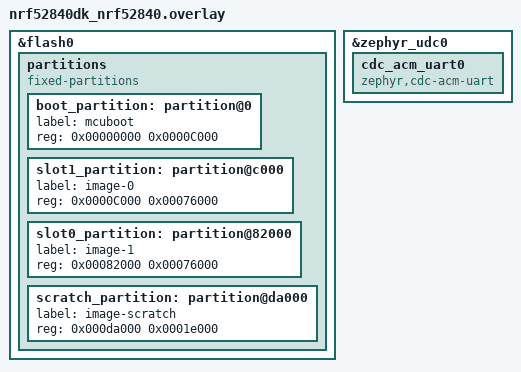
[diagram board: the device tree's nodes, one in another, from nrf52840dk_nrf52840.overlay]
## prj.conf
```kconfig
CONFIG_STDOUT_CONSOLE=y
CONFIG_USB_DEVICE_STACK=y
CONFIG_USB_DEVICE_BOS=y
CONFIG_SERIAL=y
CONFIG_USB_DEVICE_PRODUCT="Zephyr WebUSB sample"
CONFIG_USB_DEVICE_PID=0x000A
CONFIG_UART_INTERRUPT_DRIVEN=y
CONFIG_UART_LINE_CTRL=y
CONFIG_USB_DEVICE_INITIALIZE_AT_BOOT=n

CONFIG_LOG=y
CONFIG_USB_DRIVER_LOG_LEVEL_ERR=y
CONFIG_USB_DEVICE_LOG_LEVEL_ERR=y

CONFIG_FLASH=y
CONFIG_FLASH_MAP=y
CONFIG_STREAM_FLASH=y
CONFIG_IMG_MANAGER=y
CONFIG_FLASH_PAGE_LAYOUT=y

CONFIG_BOOTLOADER_MCUBOOT=y
CONFIG_MCUBOOT_EXTRA_IMGTOOL_ARGS="--version 1.2"
CONFIG_MCUBOOT_SIGNATURE_KEY_FILE="bootloader/mcuboot/root-rsa-2048.pem"
```

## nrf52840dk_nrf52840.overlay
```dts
/delete-node/ &boot_partition;
/delete-node/ &slot0_partition;
/delete-node/ &slot1_partition;
&flash0 {
    partitions {
            compatible = "fixed-partitions";
            #address-cells = <1>;
            #size-cells = <1>;
            boot_partition: partition@0 {
                label = "mcuboot";
                reg = <0x00000000 0x0000C000>;
            };
            slot1_partition: partition@c000 {
                label = "image-0";
                reg = <0x0000C000 0x00076000>;
            };
            slot0_partition: partition@82000 {
                label = "image-1";
                reg = <0x00082000 0x00076000>;
            };
            scratch_partition: partition@da000 {
                label = "image-scratch";
                reg = <0x000da000 0x0001e000>;
            };
    };
};
&zephyr_udc0 {
    cdc_acm_uart0 {
        compatible = "zephyr,cdc-acm-uart";
    };
};
```

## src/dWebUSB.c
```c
#define LOG_LEVEL CONFIG_USB_DEVICE_LOG_LEVEL
#include <zephyr/logging/log.h>
LOG_MODULE_REGISTER(webusb);

#include <zephyr/sys/byteorder.h>
#include <zephyr/usb/usb_device.h>
#include <usb_descriptor.h>

#include "dWebUSB.h"

#include <stdio.h>
#include <stdlib.h>
#include </home/peter/dfwebusb/zephyr/include/zephyr/dfu/mcuboot.h>

/* Max packet size for Bulk endpoints */
#if IS_ENABLED(CONFIG_USB_DC_HAS_HS_SUPPORT)
#define WEBUSB_BULK_EP_MPS		512
#else
#define WEBUSB_BULK_EP_MPS		64
#endif

/* Number of interfaces */
#define WEBUSB_NUM_ITF			0x01
/* Number of Endpoints in the custom interface */
#define WEBUSB_NUM_EP			0x02

#define WEBUSB_IN_EP_IDX		0
#define WEBUSB_OUT_EP_IDX		1

static struct webusb_req_handlers *req_handlers;

#define TX_MEM_ERROR 	0x05
#define TX_SIZE			20000
//setting up a buffers for echoing received data
uint8_t rx_buf[WEBUSB_BULK_EP_MPS];
static uint8_t tx_buf[TX_SIZE];
static size_t bytes_count = 0;

//template for interface descriptors
#define INITIALIZER_IF(num_ep, iface_class)				\
	{								\
		.bLength = sizeof(struct usb_if_descriptor),		\
		.bDescriptorType = USB_DESC_INTERFACE,			\
		.bInterfaceNumber = 0,					\
		.bAlternateSetting = 0,					\
		.bNumEndpoints = num_ep,				\
		.bInterfaceClass = iface_class,				\
		.bInterfaceSubClass = 0,				\
		.bInterfaceProtocol = 0,				\
		.iInterface = 0,					\
	}
//template for endpoint descriptors
#define INITIALIZER_IF_EP(addr, attr, mps, interval)			\
	{								\
		.bLength = sizeof(struct usb_ep_descriptor),		\
		.bDescriptorType = USB_DESC_ENDPOINT,			\
		.bEndpointAddress = addr,				\
		.bmAttributes = attr,					\
		.wMaxPacketSize = sys_cpu_to_le16(mps),			\
		.bInterval = interval,					\
	}
//initialise interface and endpoints descriptors
USBD_CLASS_DESCR_DEFINE(primary, 0) struct {
	struct usb_if_descriptor if0;
	struct usb_ep_descriptor if0_in_ep;
	struct usb_ep_descriptor if0_out_ep;
} __packed webusb_desc = {
	.if0 = INITIALIZER_IF(WEBUSB_NUM_EP, USB_BCC_VENDOR),
	.if0_in_ep = INITIALIZER_IF_EP(AUTO_EP_IN, USB_DC_EP_BULK,
				       WEBUSB_BULK_EP_MPS, 0),
	.if0_out_ep = INITIALIZER_IF_EP(AUTO_EP_OUT, USB_DC_EP_BULK,
					WEBUSB_BULK_EP_MPS, 0),
};

/**
 * @brief Custom handler for standard requests in order to
 *        catch the request and return the WebUSB Platform
 *        Capability Descriptor.
 *
 * @param pSetup    Information about the request to execute.
 * @param len       Size of the buffer.
 * @param data      Buffer containing the request result.
 *
 * @return  0 on success, negative errno code on fail.
 */
int webusb_custom_handle_req(struct usb_setup_packet *pSetup,
			     int32_t *len, uint8_t **data){
	LOG_DBG("");

	/* Call the callback */
	if (req_handlers && req_handlers->custom_handler) {
		return req_handlers->custom_handler(pSetup, len, data);
	}

	return -EINVAL;
}

/**
 * @brief Handler called for WebUSB vendor specific commands.
 *
 * @param pSetup    Information about the request to execute.
 * @param len       Size of the buffer.
 * @param data      Buffer containing the request result.
 *
 * @return  0 on success, negative errno code on fail.
 */
int webusb_vendor_handle_req(struct usb_setup_packet *pSetup,
			     int32_t *len, uint8_t **data){
	/* Call the callback */
	if (req_handlers && req_handlers->vendor_handler) {
		return req_handlers->vendor_handler(pSetup, len, data);
	}

	return -EINVAL;
}

/**
 * @brief Register Custom and Vendor request callbacks
 *
 * This function registers Custom and Vendor request callbacks
 * for handling the device requests.
 *
 * @param [in] handlers Pointer to WebUSB request handlers structure
 */
void webusb_register_request_handlers(struct webusb_req_handlers *handlers){
	req_handlers = handlers;
}

static void webusb_write_cb(uint8_t ep, int size, void *priv){
	//printf("\n This is write callback, ep %x size %u", ep, size);
	bytes_count = 0;
	memset(tx_buf, 0, sizeof(tx_buf)); //zeroing the receiving array
}

static void webusb_read_cb(uint8_t ep, int size, void *priv){
	struct usb_cfg_data *cfg = priv;
	//printf("\nSize count: %d", size);
	
	if(size <= 0) goto done;
	else {
		//printf("\ntransfer still active");
		memcpy(tx_buf + bytes_count, rx_buf, size);
		bytes_count += size;
		//printf("\nBytes count: %zu", bytes_count);
		if(size < WEBUSB_BULK_EP_MPS && size > 0){
		//	printf("\ntransfer finished, ready to echo");
			usb_transfer(cfg->endpoint[WEBUSB_IN_EP_IDX].ep_addr, tx_buf, bytes_count,
				USB_TRANS_WRITE, webusb_write_cb, cfg);
		}
	}
done:
	usb_transfer(ep, rx_buf, sizeof(rx_buf), USB_TRANS_READ, webusb_read_cb, cfg);
	//printf("\nReading");
}

/**
 * @brief Callback used to know the USB connection status
 *
 * @param status USB device status code.
 */
static void webusb_dev_status_cb(struct usb_cfg_data *cfg,
				 enum usb_dc_status_code status,
				 const uint8_t *param){
	ARG_UNUSED(param);
	ARG_UNUSED(cfg);

	/* Check the USB status and do needed action if required */
	switch (status) {
	case USB_DC_ERROR:
		LOG_DBG("USB device error");
		break;
	case USB_DC_RESET:
		LOG_DBG("USB device reset detected");
		break;
	case USB_DC_CONNECTED:
		LOG_DBG("USB device connected");
		break;
	case USB_DC_CONFIGURED:
		LOG_DBG("USB device configured");
		webusb_read_cb(cfg->endpoint[WEBUSB_OUT_EP_IDX].ep_addr,
			       0, cfg);
		break;
	case USB_DC_DISCONNECTED:
		LOG_DBG("USB device disconnected");
		break;
	case USB_DC_SUSPEND:
		LOG_DBG("USB device suspended");
		break;
	case USB_DC_RESUME:
		LOG_DBG("USB device resumed");
		break;
	case USB_DC_UNKNOWN:
	default:
		LOG_DBG("USB unknown state");
		break;
	}
}

/* Describe EndPoints configuration */
static struct usb_ep_cfg_data webusb_ep_data[] = {
	{
		.ep_cb = usb_transfer_ep_callback,
		.ep_addr = AUTO_EP_IN
	},
	{
		.ep_cb	= usb_transfer_ep_callback,
		.ep_addr = AUTO_EP_OUT
	}
};

//USB Device configuration structure
USBD_DEFINE_CFG_DATA(webusb_config) = {
	.usb_device_description = NULL,
	.interface_descriptor = &webusb_desc.if0,
	.cb_usb_status = webusb_dev_status_cb,
	.interface = {
		.class_handler = NULL,
		.custom_handler = webusb_custom_handle_req,
		.vendor_handler = webusb_vendor_handle_req,
	},
	.num_endpoints = ARRAY_SIZE(webusb_ep_data),
	.endpoint = webusb_ep_data
};
```

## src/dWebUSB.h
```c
#ifndef __WEBUSB_SERIAL_H__
#define __WEBUSB_SERIAL_H__

/**
 * WebUSB request handlers
 */
struct webusb_req_handlers {
	/* Handler for WebUSB Vendor specific commands */
	usb_request_handler vendor_handler;
	/**
	 * The custom request handler gets a first chance at handling
	 * the request before it is handed over to the 'chapter 9' request
	 * handler
	 */
	usb_request_handler custom_handler;
};

/**
 * @brief Register Custom and Vendor request callbacks
 *
 * Function to register Custom and Vendor request callbacks
 * for handling requests.
 *
 * @param [in] handlers Pointer to WebUSB request handlers structure
 */
void webusb_register_request_handlers(struct webusb_req_handlers *handlers);

#endif /* __WEBUSB_SERIAL_H__ */
```

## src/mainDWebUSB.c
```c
#define LOG_LEVEL CONFIG_USB_DEVICE_LOG_LEVEL
#include <zephyr/logging/log.h>
LOG_MODULE_REGISTER(main);

#include <zephyr/sys/byteorder.h>
#include <zephyr/usb/usb_device.h>
#include <zephyr/usb/bos.h>

#include <zephyr/dfu/mcuboot.h>
#include "dWebUSB.h"
#include <stdio.h>

/* Number of allowed origins */
#define NUMBER_OF_ALLOWED_ORIGINS   1

//Error for unsuccesful image header read
#define READFW_ERROR -7
//structure for storing version data from an image read
static struct versionSend {
	uint8_t maj;
	uint8_t min;
	uint16_t rev;
} v;

/* Predefined response to control commands related to MS OS 2.0 descriptors */
static const uint8_t msos2_descriptor[] = {
	/* MS OS 2.0 set header descriptor   */
	0x0A, 0x00,             /* Descriptor size (10 bytes)                 */
	0x00, 0x00,             /* MS_OS_20_SET_HEADER_DESCRIPTOR             */
	0x00, 0x00, 0x03, 0x06, /* Windows version (8.1) (0x06030000)         */
	(0x0A + 0x14 + 0x08), 0x00, /* Length of the MS OS 2.0 descriptor set */

	/* MS OS 2.0 function subset ID descriptor
	 * This means that the descriptors below will only apply to one
	 * set of interfaces
	 */
	0x08, 0x00, /* Descriptor size (8 bytes) */
	0x02, 0x00, /* MS_OS_20_SUBSET_HEADER_FUNCTION */
	0x02,       /* Index of first interface this subset applies to. */
	0x00,       /* reserved */
	(0x08 + 0x14), 0x00, /* Length of the MS OS 2.0 descriptor subset */

	/* MS OS 2.0 compatible ID descriptor */
	0x14, 0x00, /* Descriptor size                */
	0x03, 0x00, /* MS_OS_20_FEATURE_COMPATIBLE_ID */
	/* 8-byte compatible ID string, then 8-byte sub-compatible ID string */
	'W',  'I',  'N',  'U',  'S',  'B',  0x00, 0x00,
	0x00, 0x00, 0x00, 0x00, 0x00, 0x00, 0x00, 0x00
};

/* WebUSB Platform Capability Descriptor:*/
USB_DEVICE_BOS_DESC_DEFINE_CAP struct usb_bos_webusb_desc {
	struct usb_bos_platform_descriptor platform;
	struct usb_bos_capability_webusb cap;
} __packed bos_cap_webusb = {
	/* https://wicg.github.io/webusb/#webusb-platform-capability-descriptor
	 *
	 * Size of the descriptor (must equal 24),
	 * Device capability descriptor type,
	 * Platform capability type ,
	 * Set to 0 for format purposes,
	 * Platform capability UUID
	 */
	.platform = {
		.bLength = sizeof(struct usb_bos_platform_descriptor)
			+ sizeof(struct usb_bos_capability_webusb),
		.bDescriptorType = USB_DESC_DEVICE_CAPABILITY,
		.bDevCapabilityType = USB_BOS_CAPABILITY_PLATFORM,
		.bReserved = 0,
		.PlatformCapabilityUUID = {
			0x38, 0xB6, 0x08, 0x34,
			0xA9, 0x09,
			0xA0, 0x47,
			0x8B, 0xFD,
			0xA0, 0x76, 0x88, 0x15, 0xB6, 0x65,
		},
	},

	/* Protocol version supported,
	 * bRequest value for webusb requests,
	 * URL desc index for landing page 
	 */
	.cap = {
		.bcdVersion = sys_cpu_to_le16(0x0100),
		.bVendorCode = 0x01,
		.iLandingPage = 0x01
	}
};

USB_DEVICE_BOS_DESC_DEFINE_CAP struct usb_bos_msosv2_desc {
	struct usb_bos_platform_descriptor platform;
	struct usb_bos_capability_msos cap;
} __packed bos_cap_msosv2 = {
	/* Microsoft OS 2.0 Platform Capability Descriptor
	 * See https://docs.microsoft.com/en-us/windows-hardware/drivers/usbcon/
	 * microsoft-defined-usb-descriptors
	 * Adapted from the source:
	 * https://github.com/sowbug/weblight/blob/master/firmware/webusb.c
	 * (BSD-2) Thanks http://janaxelson.com/files/ms_os_20_descriptors.c
	 */
	.platform = {
		.bLength = sizeof(struct usb_bos_platform_descriptor)
			+ sizeof(struct usb_bos_capability_msos),
		.bDescriptorType = USB_DESC_DEVICE_CAPABILITY,
		.bDevCapabilityType = USB_BOS_CAPABILITY_PLATFORM,
		.bReserved = 0,
		.PlatformCapabilityUUID = {
			/**
			 * MS OS 2.0 Platform Capability ID
			 * D8DD60DF-4589-4CC7-9CD2-659D9E648A9F
			 */
			0xDF, 0x60, 0xDD, 0xD8,
			0x89, 0x45,
			0xC7, 0x4C,
			0x9C, 0xD2,
			0x65, 0x9D, 0x9E, 0x64, 0x8A, 0x9F,
		},
	},
	.cap = {
		/* Windows version (8.1) (0x06030000) */
		.dwWindowsVersion = sys_cpu_to_le32(0x06030000),
		.wMSOSDescriptorSetTotalLength =
			sys_cpu_to_le16(sizeof(msos2_descriptor)),
		.bMS_VendorCode = 0x02,
		.bAltEnumCode = 0x00
	},
};

USB_DEVICE_BOS_DESC_DEFINE_CAP struct usb_bos_capability_lpm bos_cap_lpm = {
	.bLength = sizeof(struct usb_bos_capability_lpm),
	.bDescriptorType = USB_DESC_DEVICE_CAPABILITY,
	.bDevCapabilityType = USB_BOS_CAPABILITY_EXTENSION,
	/**
	 * BIT(1) - LPM support
	 * BIT(2) - BESL support
	 */
	.bmAttributes = BIT(1) | BIT(2),
};

/* WebUSB Device Requests */
static const uint8_t webusb_allowed_origins[] = {
	/* Allowed Origins Header:
	 * https://wicg.github.io/webusb/#get-allowed-origins
	 */
	0x05, 0x00, 0x0D, 0x00, 0x01,

	/* Configuration Subset Header:
	 * https://wicg.github.io/webusb/#configuration-subset-header
	 */
	0x04, 0x01, 0x01, 0x01,

	/* Function Subset Header:
	 * https://wicg.github.io/webusb/#function-subset-header
	 */
	0x04, 0x02, 0x02, 0x01
};

/* (Landing page) URL Descriptor: https://wicg.github.io/webusb/#url-descriptor */
static const uint8_t webusb_origin_url[] = {
	/* Length, DescriptorType, Scheme */
	0x1A, 0x03, 0x01,
    'd','e','l','t','a','-','w','e','b','u','s','b','.','v','e','r','c','e','l','.','a','p','p','/'
};

/* Predefined response to control commands related to MS OS 1.0 descriptors
 * Please note that this code only defines "extended compat ID OS feature
 * descriptors" and not "extended properties OS features descriptors"
 */
#define MSOS_STRING_LENGTH	18
static struct string_desc {
	uint8_t bLength;
	uint8_t bDescriptorType;
	uint8_t bString[MSOS_STRING_LENGTH];

} __packed msos1_string_descriptor = {
	.bLength = MSOS_STRING_LENGTH,
	.bDescriptorType = USB_DESC_STRING,
	/* Signature MSFT100 */
	.bString = {
		'M', 0x00, 'S', 0x00, 'F', 0x00, 'T', 0x00,
		'1', 0x00, '0', 0x00, '0', 0x00,
		0x03, /* Vendor Code, used for a control request */
		0x00, /* Padding byte for VendorCode looks like UTF16 */
	},
};

static const uint8_t msos1_compatid_descriptor[] = {
	/* See https://github.com/pbatard/libwdi/wiki/WCID-Devices */
	/* MS OS 1.0 header section */
	0x28, 0x00, 0x00, 0x00, /* Descriptor size (40 bytes)          */
	0x00, 0x01,             /* Version 1.00                        */
	0x04, 0x00,             /* Type: Extended compat ID descriptor */
	0x01,                   /* Number of function sections         */
	0x00, 0x00, 0x00, 0x00, 0x00, 0x00, 0x00,       /* reserved    */

	/* MS OS 1.0 function section */
	0x02,     /* Index of interface this section applies to. */
	0x01,     /* reserved */
	/* 8-byte compatible ID string, then 8-byte sub-compatible ID string */
	'W',  'I',  'N',  'U',  'S',  'B',  0x00, 0x00,
	0x00, 0x00, 0x00, 0x00, 0x00, 0x00, 0x00, 0x00,
	0x00, 0x00, 0x00, 0x00, 0x00, 0x00 /* reserved */
};

/**
 * @brief Custom handler for standard requests in
 *        order to catch the request and return the
 *        WebUSB Platform Capability Descriptor.
 *
 * @param pSetup    Information about the request to execute.
 * @param len       Size of the buffer.
 * @param data      Buffer containing the request result.
 *
 * @return  0 on success, negative errno code on fail
 */
int custom_handle_req(struct usb_setup_packet *pSetup,
		      int32_t *len, uint8_t **data){
	if (usb_reqtype_is_to_device(pSetup)) {
		return -ENOTSUP;
	}

	if (USB_GET_DESCRIPTOR_TYPE(pSetup->wValue) == USB_DESC_STRING &&
	    USB_GET_DESCRIPTOR_INDEX(pSetup->wValue) == 0xEE) {
		*data = (uint8_t *)(&msos1_string_descriptor);
		*len = sizeof(msos1_string_descriptor);

		LOG_DBG("Get MS OS Descriptor v1 string");

		return 0;
	}

	return -EINVAL;
}

/**
 * @brief Handler called for vendor specific commands. This includes
 *        WebUSB allowed origins and MS OS 1.0 and 2.0 descriptors.
 *
 * @param pSetup    Information about the request to execute.
 * @param len       Size of the buffer.
 * @param data      Buffer containing the request result.
 *
 * @return  0 on success, negative errno code on fail.
 */
int vendor_handle_req(struct usb_setup_packet *pSetup,
		      int32_t *len, uint8_t **data){
	//printf("\nVendor URB received, \nRequest: 0x%02x ,", pSetup->bRequest);
	//printf("\nIndex: 0x%02x ,", pSetup->wIndex);
	//printf("\nValue: 0x%02x ,", pSetup->wValue);

	//Disregard requests with direction set to "to device"
	if (usb_reqtype_is_to_device(pSetup)) {
		return -ENOTSUP;
	}

	//Requests to host:

	/* Get Allowed origins request */
    if (pSetup->bRequest == 0x01 && pSetup->wIndex == 0x01) {
        *data = (uint8_t *)(&webusb_allowed_origins);
        *len = sizeof(webusb_allowed_origins);

        LOG_DBG("Get webusb_allowed_origins");

        return 0;
    } 
	/* Get URL request */
	else if (pSetup->bRequest == 0x01 && pSetup->wIndex == 0x02) {
        
        uint8_t index = USB_GET_DESCRIPTOR_INDEX(pSetup->wValue);

        if (index == 0U || index > NUMBER_OF_ALLOWED_ORIGINS) {
            return -ENOTSUP;
        }

        *data = (uint8_t *)(&webusb_origin_url);
        *len = sizeof(webusb_origin_url);

        LOG_DBG("Get webusb_origin_url");

        return 0;
    } 
    /* Get MS OS 2.0 Descriptors request */
	else if (pSetup->bRequest == 0x02 && pSetup->wIndex == 0x07) {

        /* 0x07 means "MS_OS_20_DESCRIPTOR_INDEX" */
        *data = (uint8_t *)(&msos2_descriptor);
        *len = sizeof(msos2_descriptor);

        LOG_DBG("Get MS OS Descriptors v2");

        return 0;
    } 
	/* Get MS OS 1.0 Descriptors request */
	else if (pSetup->bRequest == 0x03 && pSetup->wIndex == 0x04) {

        /* 0x04 means "Extended compat ID".
        * Use 0x05 instead for "Extended properties".
        */
        *data = (uint8_t *)(&msos1_compatid_descriptor);
        *len = sizeof(msos1_compatid_descriptor);

        LOG_DBG("Get MS OS Descriptors CompatibleID");

        return 0;
    } 
	/* Get ReadFW request */
	else if (pSetup->bRequest == 0x0f) {
		static struct mcuboot_img_header readHeader; //16bytes size
		int rc = boot_read_bank_header(2, &readHeader, sizeof(readHeader));
		//printf("\nHeader read status: %d",rc);
		if(rc < 0){
		return READFW_ERROR;
		}
		else {
			v.maj = readHeader.h.v1.sem_ver.major;
			v.min = readHeader.h.v1.sem_ver.minor;
			v.rev = readHeader.h.v1.sem_ver.revision; 
			*data = (uint8_t *)(&v);
			*len = sizeof(v);
			return 0;
		} 
    }
	return -ENOTSUP;
}

/* Custom and Vendor request handlers */
static struct webusb_req_handlers req_handlers = {
	.custom_handler = custom_handle_req,
	.vendor_handler = vendor_handle_req,
};

void main(void){
	int ret;

	LOG_DBG("");
    //Adding platform capability custom descriptors to Bos
	usb_bos_register_cap((void *)&bos_cap_webusb);
	usb_bos_register_cap((void *)&bos_cap_msosv2);
	usb_bos_register_cap((void *)&bos_cap_lpm);

	/* Set the custom and vendor request handlers */
	webusb_register_request_handlers(&req_handlers);

	ret = usb_enable(NULL);
	if (ret != 0) {
		LOG_ERR("Failed to enable USB");
		return;
	}
}
```

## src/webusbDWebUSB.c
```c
#define LOG_LEVEL CONFIG_USB_DEVICE_LOG_LEVEL
#include <zephyr/logging/log.h>
LOG_MODULE_REGISTER(webusb);

#include <zephyr/sys/byteorder.h>
#include <zephyr/usb/usb_device.h>
#include <usb_descriptor.h>

#include "webusb.h"

#include <stdio.h>
#include <stdlib.h>
#include </home/peter/dfwebusb/zephyr/include/zephyr/dfu/mcuboot.h>

/* Max packet size for Bulk endpoints */
#if IS_ENABLED(CONFIG_USB_DC_HAS_HS_SUPPORT)
#define WEBUSB_BULK_EP_MPS		512
#else
#define WEBUSB_BULK_EP_MPS		64
#endif

/* Number of interfaces */
#define WEBUSB_NUM_ITF			0x01
/* Number of Endpoints in the custom interface */
#define WEBUSB_NUM_EP			0x02

#define WEBUSB_IN_EP_IDX		0
#define WEBUSB_OUT_EP_IDX		1

static struct webusb_req_handlers *req_handlers;

#define TX_MEM_ERROR 	0x05
#define TX_SIZE			20000
//setting up a buffers for echoing received data
uint8_t rx_buf[WEBUSB_BULK_EP_MPS];
static uint8_t tx_buf[TX_SIZE];
static size_t bytes_count = 0;

//template for interface descriptors
#define INITIALIZER_IF(num_ep, iface_class)				\
	{								\
		.bLength = sizeof(struct usb_if_descriptor),		\
		.bDescriptorType = USB_DESC_INTERFACE,			\
		.bInterfaceNumber = 0,					\
		.bAlternateSetting = 0,					\
		.bNumEndpoints = num_ep,				\
		.bInterfaceClass = iface_class,				\
		.bInterfaceSubClass = 0,				\
		.bInterfaceProtocol = 0,				\
		.iInterface = 0,					\
	}
//template for endpoint descriptors
#define INITIALIZER_IF_EP(addr, attr, mps, interval)			\
	{								\
		.bLength = sizeof(struct usb_ep_descriptor),		\
		.bDescriptorType = USB_DESC_ENDPOINT,			\
		.bEndpointAddress = addr,				\
		.bmAttributes = attr,					\
		.wMaxPacketSize = sys_cpu_to_le16(mps),			\
		.bInterval = interval,					\
	}
//initialise interface and endpoints descriptors
USBD_CLASS_DESCR_DEFINE(primary, 0) struct {
	struct usb_if_descriptor if0;
	struct usb_ep_descriptor if0_in_ep;
	struct usb_ep_descriptor if0_out_ep;
} __packed webusb_desc = {
	.if0 = INITIALIZER_IF(WEBUSB_NUM_EP, USB_BCC_VENDOR),
	.if0_in_ep = INITIALIZER_IF_EP(AUTO_EP_IN, USB_DC_EP_BULK,
				       WEBUSB_BULK_EP_MPS, 0),
	.if0_out_ep = INITIALIZER_IF_EP(AUTO_EP_OUT, USB_DC_EP_BULK,
					WEBUSB_BULK_EP_MPS, 0),
};

/**
 * @brief Custom handler for standard requests in order to
 *        catch the request and return the WebUSB Platform
 *        Capability Descriptor.
 *
 * @param pSetup    Information about the request to execute.
 * @param len       Size of the buffer.
 * @param data      Buffer containing the request result.
 *
 * @return  0 on success, negative errno code on fail.
 */
int webusb_custom_handle_req(struct usb_setup_packet *pSetup,
			     int32_t *len, uint8_t **data){
	LOG_DBG("");

	/* Call the callback */
	if (req_handlers && req_handlers->custom_handler) {
		return req_handlers->custom_handler(pSetup, len, data);
	}

	return -EINVAL;
}

/**
 * @brief Handler called for WebUSB vendor specific commands.
 *
 * @param pSetup    Information about the request to execute.
 * @param len       Size of the buffer.
 * @param data      Buffer containing the request result.
 *
 * @return  0 on success, negative errno code on fail.
 */
int webusb_vendor_handle_req(struct usb_setup_packet *pSetup,
			     int32_t *len, uint8_t **data){
	/* Call the callback */
	if (req_handlers && req_handlers->vendor_handler) {
		return req_handlers->vendor_handler(pSetup, len, data);
	}

	return -EINVAL;
}

/**
 * @brief Register Custom and Vendor request callbacks
 *
 * This function registers Custom and Vendor request callbacks
 * for handling the device requests.
 *
 * @param [in] handlers Pointer to WebUSB request handlers structure
 */
void webusb_register_request_handlers(struct webusb_req_handlers *handlers){
	req_handlers = handlers;
}

static void webusb_write_cb(uint8_t ep, int size, void *priv){
	//printf("\n This is write callback, ep %x size %u", ep, size);
	bytes_count = 0;
	memset(tx_buf, 0, sizeof(tx_buf)); //zeroing the receiving array
}

static void webusb_read_cb(uint8_t ep, int size, void *priv){
	struct usb_cfg_data *cfg = priv;
	//printf("\nSize count: %d", size);
	
	if(size <= 0) goto done;
	else {
		//printf("\ntransfer still active");
		memcpy(tx_buf + bytes_count, rx_buf, size);
		bytes_count += size;
		//printf("\nBytes count: %zu", bytes_count);
		if(size < WEBUSB_BULK_EP_MPS && size > 0){
		//	printf("\ntransfer finished, ready to echo");
			usb_transfer(cfg->endpoint[WEBUSB_IN_EP_IDX].ep_addr, tx_buf, bytes_count,
				USB_TRANS_WRITE, webusb_write_cb, cfg);
		}
	}
done:
	usb_transfer(ep, rx_buf, sizeof(rx_buf), USB_TRANS_READ, webusb_read_cb, cfg);
	//printf("\nReading");
}

/**
 * @brief Callback used to know the USB connection status
 *
 * @param status USB device status code.
 */
static void webusb_dev_status_cb(struct usb_cfg_data *cfg,
				 enum usb_dc_status_code status,
				 const uint8_t *param){
	ARG_UNUSED(param);
	ARG_UNUSED(cfg);

	/* Check the USB status and do needed action if required */
	switch (status) {
	case USB_DC_ERROR:
		LOG_DBG("USB device error");
		break;
	case USB_DC_RESET:
		LOG_DBG("USB device reset detected");
		break;
	case USB_DC_CONNECTED:
		LOG_DBG("USB device connected");
		break;
	case USB_DC_CONFIGURED:
		LOG_DBG("USB device configured");
		webusb_read_cb(cfg->endpoint[WEBUSB_OUT_EP_IDX].ep_addr,
			       0, cfg);
		break;
	case USB_DC_DISCONNECTED:
		LOG_DBG("USB device disconnected");
		break;
	case USB_DC_SUSPEND:
		LOG_DBG("USB device suspended");
		break;
	case USB_DC_RESUME:
		LOG_DBG("USB device resumed");
		break;
	case USB_DC_UNKNOWN:
	default:
		LOG_DBG("USB unknown state");
		break;
	}
}

/* Describe EndPoints configuration */
static struct usb_ep_cfg_data webusb_ep_data[] = {
	{
		.ep_cb = usb_transfer_ep_callback,
		.ep_addr = AUTO_EP_IN
	},
	{
		.ep_cb	= usb_transfer_ep_callback,
		.ep_addr = AUTO_EP_OUT
	}
};

//USB Device configuration structure
USBD_DEFINE_CFG_DATA(webusb_config) = {
	.usb_device_description = NULL,
	.interface_descriptor = &webusb_desc.if0,
	.cb_usb_status = webusb_dev_status_cb,
	.interface = {
		.class_handler = NULL,
		.custom_handler = webusb_custom_handle_req,
		.vendor_handler = webusb_vendor_handle_req,
	},
	.num_endpoints = ARRAY_SIZE(webusb_ep_data),
	.endpoint = webusb_ep_data
};
```
